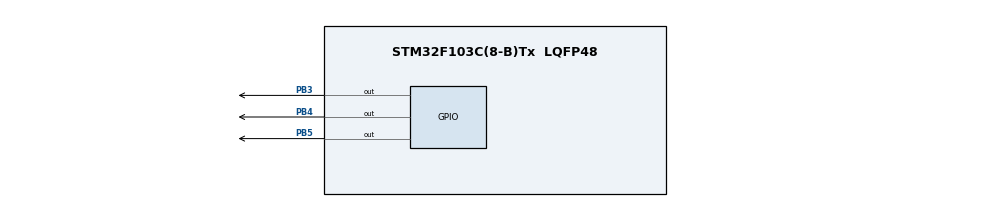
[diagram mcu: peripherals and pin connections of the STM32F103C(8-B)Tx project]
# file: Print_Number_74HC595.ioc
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Mcu.Family=STM32F1
Mcu.Name=STM32F103C(8-B)Tx
Mcu.Package=LQFP48
NVIC.PriorityGroup=NVIC_PRIORITYGROUP_4
PA13.Mode=Serial_Wire
PA13.Signal=SYS_JTMS-SWDIO
PA14.Mode=Serial_Wire
PA14.Signal=SYS_JTCK-SWCLK
PB3.Signal=GPIO_Output
PB4.Signal=GPIO_Output
PB5.Signal=GPIO_Output
ProjectManager.HeapSize=0x200
ProjectManager.StackSize=0x400
ProjectManager.TargetToolchain=MDK-ARM V5.32
RCC.APB1Freq_Value=8000000
RCC.APB2Freq_Value=8000000
board=custom

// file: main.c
/* USER CODE BEGIN Header */
/**
  ******************************************************************************
  * @file           : main.c
  * @brief          : Main program body
  ******************************************************************************
  * @attention
  *
  * Copyright (c) 2023 STMicroelectronics.
  * All rights reserved.
  *
  * This software is licensed under terms that can be found in the LICENSE file
  * in the root directory of this software component.
  * If no LICENSE file comes with this software, it is provided AS-IS.
  *
  ******************************************************************************
  */
/* USER CODE END Header */
#include "main.h"

/* USER CODE BEGIN Includes */
#define CLK_Pin  GPIO_PIN_3
#define DAT_Pin  GPIO_PIN_5
#define LAT_Pin  GPIO_PIN_4
#define LEDOFF   10
#define LED_MINUS    11
/* USER CODE END Includes */

void SystemClock_Config(void);
static void MX_GPIO_Init(void);

/* USER CODE BEGIN 0 */

const uint8_t LEDCODE[] = {0x02,0x9E,0x24,0x0C,0x98,0x48,0x40,0x1E,0x00,0x08,0xFF,0xFD};
// LEDCODE[] = {0,1,2,3,4,5,6,7,8,9,Led_Off, LEd_minus}
void LED_CLK(uint32_t n)
	{

		while (n>0) {

			HAL_GPIO_WritePin(GPIOB,CLK_Pin,1);

			HAL_GPIO_WritePin(GPIOB,CLK_Pin,0);

			n = n - 1;
	}
	}

void LED_Display(uint8_t n) {
	for(int i=0;i<8;i++)
			{
				//HAL_GPIO_WritePin(GPIOB,DAT_Pin,LEDCODE[n]&0B00000001<<i);
				HAL_GPIO_WritePin(GPIOB,DAT_Pin,LEDCODE[n]&0x01<<i);
				LED_CLK(1);
			}
}

void Print_Number(int32_t number)
{
	uint8_t minusFlag;

	if(number <0)
	{
		number = number/(-1);
		minusFlag = 1;
	}
	else
		minusFlag = 0;

	for(uint32_t i=1;i<10000001;i=i*10)
	{
		if(number/i==0)
		{
			if(minusFlag==1)
			{
				LED_Display(LED_MINUS );
				minusFlag = 0;
			}
			else
				LED_Display(LEDOFF);

		}
		else
			LED_Display((number/i)%10);
	}
}
/* USER CODE END 0 */

int main(void)
{

  /* MCU Configuration--------------------------------------------------------*/

  /* Reset of all peripherals, Initializes the Flash interface and the Systick. */
  HAL_Init();

  /* Configure the system clock */
  SystemClock_Config();

  /* Initialize all configured peripherals */
  MX_GPIO_Init();
  /* USER CODE BEGIN 2 */
	HAL_GPIO_WritePin(GPIOB, GPIO_PIN_3, GPIO_PIN_RESET); // CLK

	HAL_GPIO_WritePin(GPIOB, GPIO_PIN_4, GPIO_PIN_RESET); // SEL

	HAL_GPIO_WritePin(GPIOB, GPIO_PIN_5, GPIO_PIN_RESET); // DATA

	Print_Number(-1234567);

	HAL_GPIO_WritePin(GPIOB,LAT_Pin,GPIO_PIN_SET);
	HAL_GPIO_WritePin(GPIOB,LAT_Pin,GPIO_PIN_RESET);
    /* USER CODE END WHILE */

  /* USER CODE END 2 */

  /* Infinite loop */
  while (1)
  {

  }
}

void SystemClock_Config(void)
{
  RCC_OscInitTypeDef RCC_OscInitStruct = {0};
  RCC_ClkInitTypeDef RCC_ClkInitStruct = {0};

  /** Initializes the RCC Oscillators according to the specified parameters
  * in the RCC_OscInitTypeDef structure.
  */
  RCC_OscInitStruct.OscillatorType = RCC_OSCILLATORTYPE_HSI;
  RCC_OscInitStruct.HSIState = RCC_HSI_ON;
  RCC_OscInitStruct.HSICalibrationValue = RCC_HSICALIBRATION_DEFAULT;
  RCC_OscInitStruct.PLL.PLLState = RCC_PLL_NONE;
  if (HAL_RCC_OscConfig(&RCC_OscInitStruct) != HAL_OK)
  {
    Error_Handler();
  }

  /** Initializes the CPU, AHB and APB buses clocks
  */
  RCC_ClkInitStruct.ClockType = RCC_CLOCKTYPE_HCLK|RCC_CLOCKTYPE_SYSCLK
                              |RCC_CLOCKTYPE_PCLK1|RCC_CLOCKTYPE_PCLK2;
  RCC_ClkInitStruct.SYSCLKSource = RCC_SYSCLKSOURCE_HSI;
  RCC_ClkInitStruct.AHBCLKDivider = RCC_SYSCLK_DIV1;
  RCC_ClkInitStruct.APB1CLKDivider = RCC_HCLK_DIV1;
  RCC_ClkInitStruct.APB2CLKDivider = RCC_HCLK_DIV1;

  if (HAL_RCC_ClockConfig(&RCC_ClkInitStruct, FLASH_LATENCY_0) != HAL_OK)
  {
    Error_Handler();
  }
}

static void MX_GPIO_Init(void)
{
  GPIO_InitTypeDef GPIO_InitStruct = {0};

  /* GPIO Ports Clock Enable */
  __HAL_RCC_GPIOA_CLK_ENABLE();
  __HAL_RCC_GPIOB_CLK_ENABLE();

  /*Configure GPIO pin Output Level */
  HAL_GPIO_WritePin(GPIOB, GPIO_PIN_3|GPIO_PIN_4|GPIO_PIN_5, GPIO_PIN_RESET);

  /*Configure GPIO pins : PB3 PB4 PB5 */
  GPIO_InitStruct.Pin = GPIO_PIN_3|GPIO_PIN_4|GPIO_PIN_5;
  GPIO_InitStruct.Mode = GPIO_MODE_OUTPUT_PP;
  GPIO_InitStruct.Pull = GPIO_NOPULL;
  GPIO_InitStruct.Speed = GPIO_SPEED_FREQ_LOW;
  HAL_GPIO_Init(GPIOB, &GPIO_InitStruct);

}

void Error_Handler(void)
{
  __disable_irq();
  while (1)
  {
  }
}
